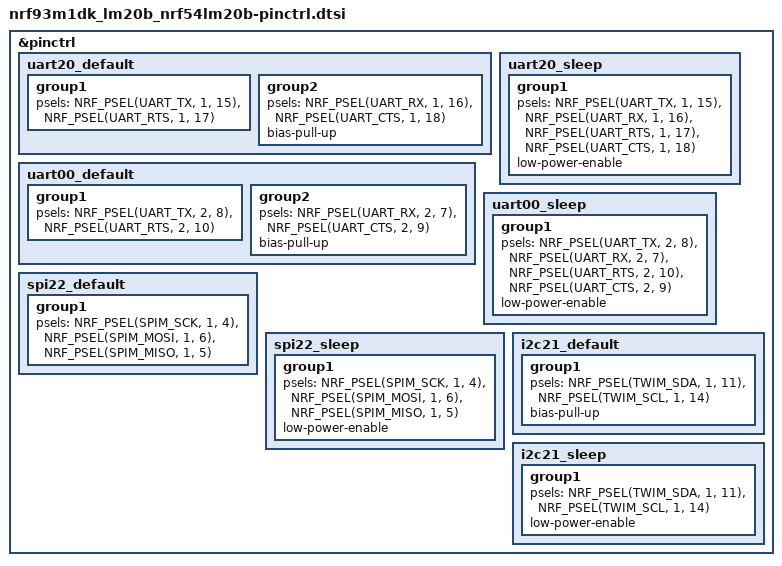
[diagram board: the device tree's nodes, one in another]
/*
 * Copyright (c) 2026 Nordic Semiconductor ASA
 *
 * SPDX-License-Identifier: Apache-2.0
 */

/*
 * TODO: pinmap for DK v0.5.0 (nRF54LM20B). Initial values are copied from
 * nRF93M1 DK v0.4.0 (nRF54L15) and must be reviewed against the schematic.
 */

&pinctrl {
	/omit-if-no-ref/ uart20_default: uart20_default {
		group1 {
			psels = <NRF_PSEL(UART_TX, 1, 15)>,
				<NRF_PSEL(UART_RTS, 1, 17)>;
		};

		group2 {
			psels = <NRF_PSEL(UART_RX, 1, 16)>,
				<NRF_PSEL(UART_CTS, 1, 18)>;
			bias-pull-up;
		};
	};

	/omit-if-no-ref/ uart20_sleep: uart20_sleep {
		group1 {
			psels = <NRF_PSEL(UART_TX, 1, 15)>,
				<NRF_PSEL(UART_RX, 1, 16)>,
				<NRF_PSEL(UART_RTS, 1, 17)>,
				<NRF_PSEL(UART_CTS, 1, 18)>;
			low-power-enable;
		};
	};

	/omit-if-no-ref/ uart00_default: uart00_default {
		group1 {
			psels = <NRF_PSEL(UART_TX, 2, 8)>,
				<NRF_PSEL(UART_RTS, 2, 10)>;
		};

		group2 {
			psels = <NRF_PSEL(UART_RX, 2, 7)>,
				<NRF_PSEL(UART_CTS, 2, 9)>;
			bias-pull-up;
		};
	};

	/omit-if-no-ref/ uart00_sleep: uart00_sleep {
		group1 {
			psels = <NRF_PSEL(UART_TX, 2, 8)>,
				<NRF_PSEL(UART_RX, 2, 7)>,
				<NRF_PSEL(UART_RTS, 2, 10)>,
				<NRF_PSEL(UART_CTS, 2, 9)>;
			low-power-enable;
		};
	};

	/omit-if-no-ref/ spi22_default: spi22_default {
		group1 {
			psels = <NRF_PSEL(SPIM_SCK, 1, 4)>,
				<NRF_PSEL(SPIM_MOSI, 1, 6)>,
				<NRF_PSEL(SPIM_MISO, 1, 5)>;
		};
	};

	/omit-if-no-ref/ spi22_sleep: spi22_sleep {
		group1 {
			psels = <NRF_PSEL(SPIM_SCK, 1, 4)>,
				<NRF_PSEL(SPIM_MOSI, 1, 6)>,
				<NRF_PSEL(SPIM_MISO, 1, 5)>;
			low-power-enable;
		};
	};

	/omit-if-no-ref/ i2c21_default: i2c21_default {
		group1 {
			psels = <NRF_PSEL(TWIM_SDA, 1, 11)>,
				<NRF_PSEL(TWIM_SCL, 1, 14)>;
			bias-pull-up;
		};
	};

	/omit-if-no-ref/ i2c21_sleep: i2c21_sleep {
		group1 {
			psels = <NRF_PSEL(TWIM_SDA, 1, 11)>,
				<NRF_PSEL(TWIM_SCL, 1, 14)>;
			low-power-enable;
		};
	};
};
